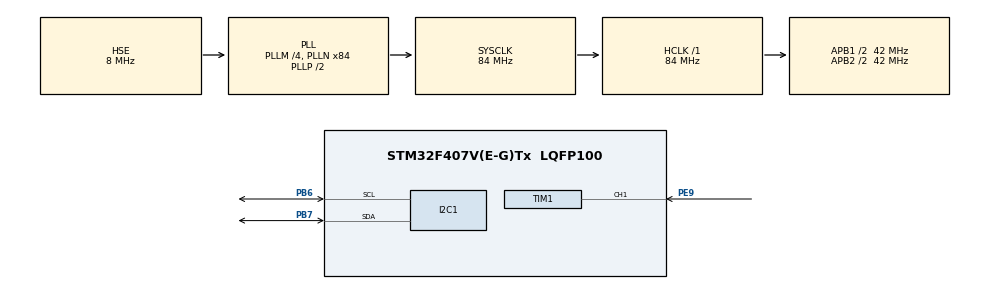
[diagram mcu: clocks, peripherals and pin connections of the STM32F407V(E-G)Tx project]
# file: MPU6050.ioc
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Mcu.Family=STM32F4
Mcu.Name=STM32F407V(E-G)Tx
Mcu.Package=LQFP100
NVIC.PriorityGroup=NVIC_PRIORITYGROUP_4
NVIC.TIM1_CC_IRQn=true\:0\:0\:false\:false\:true\:true\:true
PB6.Mode=I2C
PB6.Signal=I2C1_SCL
PB7.Mode=I2C
PB7.Signal=I2C1_SDA
PE9.Signal=S_TIM1_CH1
PH0-OSC_IN.Mode=HSE-External-Oscillator
PH0-OSC_IN.Signal=RCC_OSC_IN
PH1-OSC_OUT.Mode=HSE-External-Oscillator
PH1-OSC_OUT.Signal=RCC_OSC_OUT
ProjectManager.HeapSize=0x200
ProjectManager.StackSize=0x400
ProjectManager.TargetToolchain=STM32CubeIDE
RCC.48MHZClocksFreq_Value=42000000
RCC.AHBFreq_Value=84000000
RCC.APB1CLKDivider=RCC_HCLK_DIV2
RCC.APB1Freq_Value=42000000
RCC.APB1TimFreq_Value=84000000
RCC.APB2CLKDivider=RCC_HCLK_DIV2
RCC.APB2Freq_Value=42000000
RCC.APB2TimFreq_Value=84000000
RCC.CortexFreq_Value=84000000
RCC.HCLKFreq_Value=84000000
RCC.HSE_VALUE=8000000
RCC.HSI_VALUE=16000000
RCC.LSE_VALUE=32768
RCC.PLLM=4
RCC.PLLN=84
RCC.PLLSourceVirtual=RCC_PLLSOURCE_HSE
RCC.SYSCLKFreq_VALUE=84000000
RCC.SYSCLKSource=RCC_SYSCLKSOURCE_PLLCLK
RCC.VCOOutputFreq_Value=168000000
SH.S_TIM1_CH1.0=TIM1_CH1,Input_Capture1_from_TI1
TIM1.Channel-Input_Capture1_from_TI1=TIM_CHANNEL_1
TIM1.Period=0xffff-1
TIM1.Prescaler=84-1
board=custom

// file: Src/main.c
/* USER CODE BEGIN Header */
/**
  ******************************************************************************
  * @file           : main.c
  * @brief          : Main program body
  ******************************************************************************
  * @attention
  *
  * <h2><center>&copy; Copyright (c) 2021 STMicroelectronics.
  * All rights reserved.</center></h2>
  *
  * This software component is licensed by ST under BSD 3-Clause license,
  * the "License"; You may not use this file except in compliance with the
  * License. You may obtain a copy of the License at:
  *                        opensource.org/licenses/BSD-3-Clause
  *
  ******************************************************************************
  */
/* USER CODE END Header */

#include "main.h"

/* USER CODE BEGIN Includes */
#include "MPU6050.h"
/* USER CODE END Includes */

/* USER CODE BEGIN PTD */

float PitchValue,RollValue,temperature;
char message[100];

uint32_t SystickMs=0;
uint32_t SystickSecond=0;
/* USER CODE END PTD */

I2C_HandleTypeDef hi2c1;

TIM_HandleTypeDef htim1;

void SystemClock_Config(void);
static void MX_GPIO_Init(void);
static void MX_I2C1_Init(void);
static void MX_TIM1_Init(void);

int main(void)
{

  /* MCU Configuration--------------------------------------------------------*/

  /* Reset of all peripherals, Initializes the Flash interface and the Systick. */
  HAL_Init();

  /* Configure the system clock */
  SystemClock_Config();

  /* Initialize all configured peripherals */
  MX_GPIO_Init();
  MX_I2C1_Init();
  MX_TIM1_Init();
  /* USER CODE BEGIN 2 */
  HAL_TIM_IC_Start(&htim1, TIM_CHANNEL_1);
  while(!MPU6050Init())
  {

	  sprintf(message,"MPU6050 Error.Check wire connections...\n");
	  HAL_Delay(1000);

  }

  sprintf(message,"Wait for initialization and calibration\n");
  MPU6050Initialization();
  /* USER CODE END 2 */

  /* Infinite loop */
  while (1)
  {

    /* USER CODE BEGIN 3 */
  	if(MPU6050Init())
  	{
  		getAllDatas();
  		PitchValue=getPitch();
  	    RollValue=getRoll();
  	    temperature=getTemperature();
  	}
  }
  /* USER CODE END 3 */
}

void SystemClock_Config(void)
{
  RCC_OscInitTypeDef RCC_OscInitStruct = {0};
  RCC_ClkInitTypeDef RCC_ClkInitStruct = {0};

  /** Configure the main internal regulator output voltage
  */
  __HAL_RCC_PWR_CLK_ENABLE();
  __HAL_PWR_VOLTAGESCALING_CONFIG(PWR_REGULATOR_VOLTAGE_SCALE1);
  /** Initializes the CPU, AHB and APB busses clocks
  */
  RCC_OscInitStruct.OscillatorType = RCC_OSCILLATORTYPE_HSE;
  RCC_OscInitStruct.HSEState = RCC_HSE_ON;
  RCC_OscInitStruct.PLL.PLLState = RCC_PLL_ON;
  RCC_OscInitStruct.PLL.PLLSource = RCC_PLLSOURCE_HSE;
  RCC_OscInitStruct.PLL.PLLM = 4;
  RCC_OscInitStruct.PLL.PLLN = 84;
  RCC_OscInitStruct.PLL.PLLP = RCC_PLLP_DIV2;
  RCC_OscInitStruct.PLL.PLLQ = 4;
  if (HAL_RCC_OscConfig(&RCC_OscInitStruct) != HAL_OK)
  {
    Error_Handler();
  }
  /** Initializes the CPU, AHB and APB busses clocks
  */
  RCC_ClkInitStruct.ClockType = RCC_CLOCKTYPE_HCLK|RCC_CLOCKTYPE_SYSCLK
                              |RCC_CLOCKTYPE_PCLK1|RCC_CLOCKTYPE_PCLK2;
  RCC_ClkInitStruct.SYSCLKSource = RCC_SYSCLKSOURCE_PLLCLK;
  RCC_ClkInitStruct.AHBCLKDivider = RCC_SYSCLK_DIV1;
  RCC_ClkInitStruct.APB1CLKDivider = RCC_HCLK_DIV2;
  RCC_ClkInitStruct.APB2CLKDivider = RCC_HCLK_DIV2;

  if (HAL_RCC_ClockConfig(&RCC_ClkInitStruct, FLASH_LATENCY_2) != HAL_OK)
  {
    Error_Handler();
  }
}

static void MX_I2C1_Init(void)
{

  hi2c1.Instance = I2C1;
  hi2c1.Init.ClockSpeed = 100000;
  hi2c1.Init.DutyCycle = I2C_DUTYCYCLE_2;
  hi2c1.Init.OwnAddress1 = 0;
  hi2c1.Init.AddressingMode = I2C_ADDRESSINGMODE_7BIT;
  hi2c1.Init.DualAddressMode = I2C_DUALADDRESS_DISABLE;
  hi2c1.Init.OwnAddress2 = 0;
  hi2c1.Init.GeneralCallMode = I2C_GENERALCALL_DISABLE;
  hi2c1.Init.NoStretchMode = I2C_NOSTRETCH_DISABLE;
  if (HAL_I2C_Init(&hi2c1) != HAL_OK)
  {
    Error_Handler();
  }

}

static void MX_TIM1_Init(void)
{

  TIM_MasterConfigTypeDef sMasterConfig = {0};
  TIM_IC_InitTypeDef sConfigIC = {0};

  htim1.Instance = TIM1;
  htim1.Init.Prescaler = 84-1;
  htim1.Init.CounterMode = TIM_COUNTERMODE_UP;
  htim1.Init.Period = 0xffff-1;
  htim1.Init.ClockDivision = TIM_CLOCKDIVISION_DIV1;
  htim1.Init.RepetitionCounter = 0;
  htim1.Init.AutoReloadPreload = TIM_AUTORELOAD_PRELOAD_DISABLE;
  if (HAL_TIM_IC_Init(&htim1) != HAL_OK)
  {
    Error_Handler();
  }
  sMasterConfig.MasterOutputTrigger = TIM_TRGO_RESET;
  sMasterConfig.MasterSlaveMode = TIM_MASTERSLAVEMODE_DISABLE;
  if (HAL_TIMEx_MasterConfigSynchronization(&htim1, &sMasterConfig) != HAL_OK)
  {
    Error_Handler();
  }
  sConfigIC.ICPolarity = TIM_INPUTCHANNELPOLARITY_RISING;
  sConfigIC.ICSelection = TIM_ICSELECTION_DIRECTTI;
  sConfigIC.ICPrescaler = TIM_ICPSC_DIV1;
  sConfigIC.ICFilter = 0;
  if (HAL_TIM_IC_ConfigChannel(&htim1, &sConfigIC, TIM_CHANNEL_1) != HAL_OK)
  {
    Error_Handler();
  }

}

static void MX_GPIO_Init(void)
{

  /* GPIO Ports Clock Enable */
  __HAL_RCC_GPIOH_CLK_ENABLE();
  __HAL_RCC_GPIOE_CLK_ENABLE();
  __HAL_RCC_GPIOB_CLK_ENABLE();

}

void Error_Handler(void)
{
}

/************************ (C) COPYRIGHT STMicroelectronics *****END OF FILE****/
